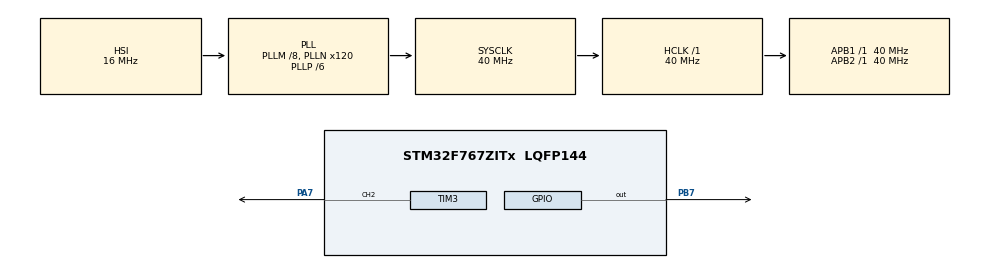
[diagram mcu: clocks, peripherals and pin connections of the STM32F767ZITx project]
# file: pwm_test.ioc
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CORTEX_M7.default_mode_Activation=1
Mcu.Family=STM32F7
Mcu.Name=STM32F767ZITx
Mcu.Package=LQFP144
NVIC.PriorityGroup=NVIC_PRIORITYGROUP_4
PA13.Mode=Serial_Wire
PA13.Signal=SYS_JTMS-SWDIO
PA14.Mode=Serial_Wire
PA14.Signal=SYS_JTCK-SWCLK
PA7.Signal=S_TIM3_CH2
PB7.Signal=GPIO_Output
ProjectManager.HeapSize=0x200
ProjectManager.StackSize=0x400
ProjectManager.TargetToolchain=STM32CubeIDE
RCC.AHBFreq_Value=40000000
RCC.APB1Freq_Value=40000000
RCC.APB1TimFreq_Value=40000000
RCC.APB2Freq_Value=40000000
RCC.APB2TimFreq_Value=40000000
RCC.CortexFreq_Value=40000000
RCC.HCLKFreq_Value=40000000
RCC.HSE_VALUE=25000000
RCC.HSI_VALUE=16000000
RCC.LSE_VALUE=32768
RCC.PLLM=8
RCC.PLLN=120
RCC.PLLP=RCC_PLLP_DIV6
RCC.SYSCLKFreq_VALUE=40000000
RCC.SYSCLKSource=RCC_SYSCLKSOURCE_PLLCLK
RCC.USBFreq_Value=120000000
RCC.VCOOutputFreq_Value=240000000
SH.S_TIM3_CH2.0=TIM3_CH2,PWM Generation2 CH2
TIM3.Channel-PWM\ Generation2\ CH2=TIM_CHANNEL_2
TIM3.Period=999
board=custom

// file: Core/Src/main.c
/* USER CODE BEGIN Header */
/**
  ******************************************************************************
  * @file           : main.c
  * @brief          : Main program body
  ******************************************************************************
  * @attention
  *
  * Copyright (c) 2025 STMicroelectronics.
  * All rights reserved.
  *
  * This software is licensed under terms that can be found in the LICENSE file
  * in the root directory of this software component.
  * If no LICENSE file comes with this software, it is provided AS-IS.
  *
  ******************************************************************************
  */
/* USER CODE END Header */
#include "main.h"

TIM_HandleTypeDef htim3;

void SystemClock_Config(void);
static void MPU_Config(void);
static void MX_GPIO_Init(void);
static void MX_TIM3_Init(void);

int main(void)
{

  /* USER CODE BEGIN 1 */
	/* Enable I-Cache---------------------------------------------------------*/
  SCB_EnableICache();

	  /* Enable D-Cache---------------------------------------------------------*/
  SCB_EnableDCache();/* Enable I-Cache---------------------------------------------------------*/

  /* USER CODE END 1 */

  /* MPU Configuration--------------------------------------------------------*/
  MPU_Config();

  /* MCU Configuration--------------------------------------------------------*/

  /* Reset of all peripherals, Initializes the Flash interface and the Systick. */
  HAL_Init();

  /* Configure the system clock */
  SystemClock_Config();

  /* Initialize all configured peripherals */
  MX_GPIO_Init();
  MX_TIM3_Init();
  /* USER CODE BEGIN 2 */
  uint16_t duty_cycle = 0;

  /* USER CODE END 2 */

  /* Infinite loop */
  while (1)
  {

    /* USER CODE BEGIN 3 */
	  __HAL_TIM_SET_COMPARE(&htim3, TIM_CHANNEL_2, duty_cycle);
	  duty_cycle += 100;
	  if(duty_cycle == 900) {
		  duty_cycle = 0;
	  }
	  HAL_Delay(10);
  }
  /* USER CODE END 3 */
}

void SystemClock_Config(void)
{
  RCC_OscInitTypeDef RCC_OscInitStruct = {0};
  RCC_ClkInitTypeDef RCC_ClkInitStruct = {0};

  /** Configure the main internal regulator output voltage
  */
  __HAL_RCC_PWR_CLK_ENABLE();
  __HAL_PWR_VOLTAGESCALING_CONFIG(PWR_REGULATOR_VOLTAGE_SCALE3);

  /** Initializes the RCC Oscillators according to the specified parameters
  * in the RCC_OscInitTypeDef structure.
  */
  RCC_OscInitStruct.OscillatorType = RCC_OSCILLATORTYPE_HSI;
  RCC_OscInitStruct.HSIState = RCC_HSI_ON;
  RCC_OscInitStruct.HSICalibrationValue = RCC_HSICALIBRATION_DEFAULT;
  RCC_OscInitStruct.PLL.PLLState = RCC_PLL_ON;
  RCC_OscInitStruct.PLL.PLLSource = RCC_PLLSOURCE_HSI;
  RCC_OscInitStruct.PLL.PLLM = 8;
  RCC_OscInitStruct.PLL.PLLN = 120;
  RCC_OscInitStruct.PLL.PLLP = RCC_PLLP_DIV6;
  RCC_OscInitStruct.PLL.PLLQ = 2;
  RCC_OscInitStruct.PLL.PLLR = 2;
  if (HAL_RCC_OscConfig(&RCC_OscInitStruct) != HAL_OK)
  {
    Error_Handler();
  }

  /** Initializes the CPU, AHB and APB buses clocks
  */
  RCC_ClkInitStruct.ClockType = RCC_CLOCKTYPE_HCLK|RCC_CLOCKTYPE_SYSCLK
                              |RCC_CLOCKTYPE_PCLK1|RCC_CLOCKTYPE_PCLK2;
  RCC_ClkInitStruct.SYSCLKSource = RCC_SYSCLKSOURCE_PLLCLK;
  RCC_ClkInitStruct.AHBCLKDivider = RCC_SYSCLK_DIV1;
  RCC_ClkInitStruct.APB1CLKDivider = RCC_HCLK_DIV1;
  RCC_ClkInitStruct.APB2CLKDivider = RCC_HCLK_DIV1;

  if (HAL_RCC_ClockConfig(&RCC_ClkInitStruct, FLASH_LATENCY_1) != HAL_OK)
  {
    Error_Handler();
  }
}

static void MX_TIM3_Init(void)
{

  TIM_MasterConfigTypeDef sMasterConfig = {0};
  TIM_OC_InitTypeDef sConfigOC = {0};

  htim3.Instance = TIM3;
  htim3.Init.Prescaler = 0;
  htim3.Init.CounterMode = TIM_COUNTERMODE_UP;
  htim3.Init.Period = 999;
  htim3.Init.ClockDivision = TIM_CLOCKDIVISION_DIV1;
  htim3.Init.AutoReloadPreload = TIM_AUTORELOAD_PRELOAD_DISABLE;
  if (HAL_TIM_PWM_Init(&htim3) != HAL_OK)
  {
    Error_Handler();
  }
  sMasterConfig.MasterOutputTrigger = TIM_TRGO_RESET;
  sMasterConfig.MasterSlaveMode = TIM_MASTERSLAVEMODE_DISABLE;
  if (HAL_TIMEx_MasterConfigSynchronization(&htim3, &sMasterConfig) != HAL_OK)
  {
    Error_Handler();
  }
  sConfigOC.OCMode = TIM_OCMODE_PWM1;
  sConfigOC.Pulse = 0;
  sConfigOC.OCPolarity = TIM_OCPOLARITY_HIGH;
  sConfigOC.OCFastMode = TIM_OCFAST_DISABLE;
  if (HAL_TIM_PWM_ConfigChannel(&htim3, &sConfigOC, TIM_CHANNEL_2) != HAL_OK)
  {
    Error_Handler();
  }
  /* USER CODE BEGIN TIM3_Init 2 */
  HAL_TIM_Base_Start(&htim3);
  HAL_TIM_PWM_Start(&htim3, TIM_CHANNEL_2);
  /* USER CODE END TIM3_Init 2 */
  HAL_TIM_MspPostInit(&htim3);

}

static void MX_GPIO_Init(void)
{
  GPIO_InitTypeDef GPIO_InitStruct = {0};

  /* GPIO Ports Clock Enable */
  __HAL_RCC_GPIOA_CLK_ENABLE();
  __HAL_RCC_GPIOB_CLK_ENABLE();

  /*Configure GPIO pin Output Level */
  HAL_GPIO_WritePin(GPIOB, GPIO_PIN_7, GPIO_PIN_RESET);

  /*Configure GPIO pin : PB7 */
  GPIO_InitStruct.Pin = GPIO_PIN_7;
  GPIO_InitStruct.Mode = GPIO_MODE_OUTPUT_PP;
  GPIO_InitStruct.Pull = GPIO_NOPULL;
  GPIO_InitStruct.Speed = GPIO_SPEED_FREQ_LOW;
  HAL_GPIO_Init(GPIOB, &GPIO_InitStruct);

}

 /* MPU Configuration */

void MPU_Config(void)
{
  MPU_Region_InitTypeDef MPU_InitStruct = {0};

  /* Disables the MPU */
  HAL_MPU_Disable();

  /** Initializes and configures the Region and the memory to be protected
  */
  MPU_InitStruct.Enable = MPU_REGION_ENABLE;
  MPU_InitStruct.Number = MPU_REGION_NUMBER0;
  MPU_InitStruct.BaseAddress = 0x0;
  MPU_InitStruct.Size = MPU_REGION_SIZE_4GB;
  MPU_InitStruct.SubRegionDisable = 0x87;
  MPU_InitStruct.TypeExtField = MPU_TEX_LEVEL0;
  MPU_InitStruct.AccessPermission = MPU_REGION_NO_ACCESS;
  MPU_InitStruct.DisableExec = MPU_INSTRUCTION_ACCESS_DISABLE;
  MPU_InitStruct.IsShareable = MPU_ACCESS_SHAREABLE;
  MPU_InitStruct.IsCacheable = MPU_ACCESS_NOT_CACHEABLE;
  MPU_InitStruct.IsBufferable = MPU_ACCESS_NOT_BUFFERABLE;

  HAL_MPU_ConfigRegion(&MPU_InitStruct);
  /* Enables the MPU */
  HAL_MPU_Enable(MPU_PRIVILEGED_DEFAULT);

}

void Error_Handler(void)
{
  __disable_irq();
  while (1)
  {
  }
}
